AUTOSAR XML (schema 4-2-2)
package /COM_SWC
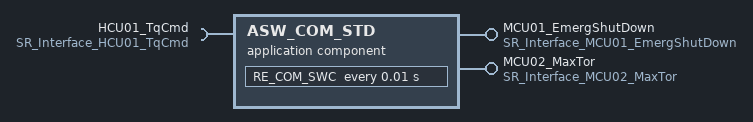
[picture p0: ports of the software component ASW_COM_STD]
  application sw component type ASW_COM_STD
    provide port MCU01_EmergShutDown: provided-interface=SR_Interface_MCU01_EmergShutDown
    provide port MCU02_MaxTor: provided-interface=SR_Interface_MCU02_MaxTor
    require port HCU01_TqCmd: nonqueued-receiver-com-spec{alive-timeout=0.3, data-element=HCU01_Tq_Cmd}, required-interface=SR_Interface_HCU01_TqCmd
    behavior IB_ASW_COM_STD
      timing event TE_RE_COM_SWC_10ms: start-on-event=RE_COM_SWC, period=0.01
      runnable RE_COM_SWC
